# STM32F303RDT6 register map
File version: 1.0
Registers are 32-bit, access not given, reset 0x0 unless marked. A register's access mark holds for its fields unless they carry their own. Offsets are from the block's base; [hi:lo] are bit positions; {n}, {i} and the like mark numbered series.

## SYSCFG
Base 0x40010000
0x00 CFGR1
  [31:26] FPU_IE, [23:22] ENCODER_MODE, [21] I2C2FMP, [20] _I2C1_FMP, [19] I2C_PB9_FMP, [18] I2C_PB8_FMP, [17] I2C_PB7_FMP, [16] I2CPB6FMP, [15] DAC2_CH1_DMA_RMP, [14] TIM7_DAC2_DMA_RMP, [13] TIM6_DAC1_DMA_RMP, [12] TIM17_DMA_RMP, [11] TIM16_DMA_RMP, [8] ADC24_DMA_RMP, [7] DAC_TRIG_RMP, [6] TIM1_ITR3_RMP, [5] USB_IT_RMP, [25:2] s, [1:0] MEM_MODE
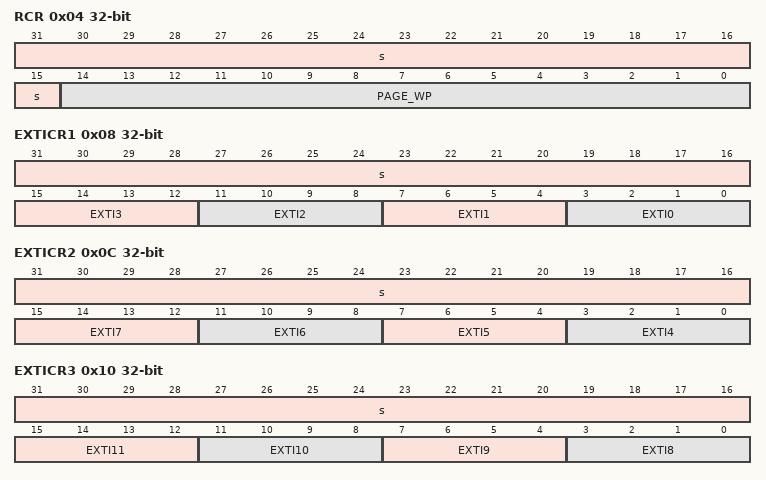
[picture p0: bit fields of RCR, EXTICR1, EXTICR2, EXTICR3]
0x04 RCR
  [31:15] s, [14:0] PAGE_WP
0x08 EXTICR1
  [31:16] s, [4n+3:4n] EXTI{n} (n=0..3)
0x0C EXTICR2
  [31:16] s, [4n-13:4n-16] EXTI{n} (n=4..7)
0x10 EXTICR3
  [31:16] s, [4n-29:4n-32] EXTI{n} (n=8..11)
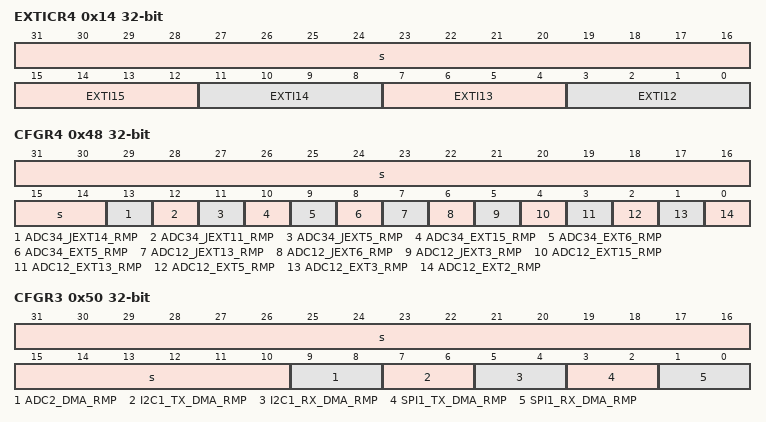
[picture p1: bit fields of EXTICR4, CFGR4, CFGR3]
0x14 EXTICR4
  [31:16] s, [4n-45:4n-48] EXTI{n} (n=12..15)
0x18 CFGR2
  [8] SRAM_PEF, [4] BYP_ADDR_PAR, [31:3] s, [2] PVD_LOCK, [1] SRAM_PARITY_LOCK, [0] LOCKUP_LOCK
0x48 CFGR4
  [31:14] s, [13] ADC34_JEXT14_RMP, [12] ADC34_JEXT11_RMP, [11] ADC34_JEXT5_RMP, [10] ADC34_EXT15_RMP, [9] ADC34_EXT6_RMP, [8] ADC34_EXT5_RMP, [7] ADC12_JEXT13_RMP, [6] ADC12_JEXT6_RMP, [5] ADC12_JEXT3_RMP, [4] ADC12_EXT15_RMP, [3] ADC12_EXT13_RMP, [2] ADC12_EXT5_RMP, [1] ADC12_EXT3_RMP, [0] ADC12_EXT2_RMP
0x50 CFGR3
  [31:10] s, [9:8] ADC2_DMA_RMP, [7:6] I2C1_TX_DMA_RMP, [5:4] I2C1_RX_DMA_RMP, [3:2] SPI1_TX_DMA_RMP, [1:0] SPI1_RX_DMA_RMP

## COMP
Base 0x40010000
0x1C COMP1_CSR
  [31] COMP1LOCK, [30] COMP1OUT, [20:18] COMPx_BLANKING, [17:16] COMP1HYST, [15] COMP1POL, [13:10] COMP1OUTSEL, [29:7] s, [6:4] COMP1INSEL, [3:2] COMP1MODE, [1] COMP1_INP_DAC, [0] COMP1EN
0x20 COMP2_CSR
  [31] COMP2LOCK, [30] COMP2OUT, [20:18] COMP2_BLANKING, [15] COMP2POL, [13:10] COMP2OUTSEL, [9] COMP2WINMODE, [29:8] s, [7] COMP2INSEL, [22:4] COMP2INMSEL, [3:2] COMP2MODE, [1] COMP2_INP_DAC, [0] COMP2EN
0x24 COMP3_CSR
  [31] COMP3LOCK, [30] COMP3OUT, [20:18] COMP3_BLANKING, [17:16] COMP3HYST, [15] COMP3POL, [13:10] COMP3OUTSEL, [7] COMP3INSEL, [6:4] COMP3INMSEL, [3:2] COMP3MODE, [29:1] s, [0] COMP3EN
0x28 COMP4_CSR
  [31] COMP4LOCK, [30] COMP4OUT, [20:18] COMP4_BLANKING, [15] COMP4POL, [13:10] COMP4OUTSEL, [9] COMP4WINMODE, [7] COMP4INSEL, [22:4] COMP4INMSEL, [3:2] COMP4MODE, [29:1] s, [0] COMP4EN
0x2C COMP5_CSR
  [31] COMP5LOCK, [30] COMP5OUT, [20:18] COMP5_BLANKING, [17:16] COMP5HYST, [15] COMP5POL, [13:10] COMP5OUTSEL, [7] COMP5INSEL, [6:4] COMP5INMSEL, [3:2] COMP5MODE, [29:1] s, [0] COMP5EN
0x30 COMP6_CSR
  [31] COMP6LOCK, [30] COMP6OUT, [20:18] COMP6_BLANKING, [15] COMP6POL, [13:10] COMP6OUTSEL, [9] COMP6WINMODE, [7] COMP6INSEL, [22:4] COMP6INMSEL, [3:2] COMP6MODE, [29:1] s, [0] COMP6EN
0x34 COMP7_CSR
  [31] COMP7LOCK, [30] COMP7OUT, [20:18] COMP7_BLANKING, [17:16] COMP7HYST, [15] COMP7POL, [13:10] COMP7OUTSEL, [7] COMP7INSEL, [6:4] COMP7INMSEL, [3:2] COMP7MODE, [29:1] s, [0] COMP7EN

## OPAMP
Base 0x40010000
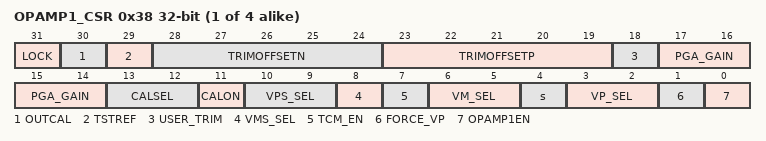
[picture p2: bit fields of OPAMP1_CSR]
{0x34+4i} OPAMP{i}_CSR (i=1..4)
  [31] LOCK, [30] OUTCAL, [29] TSTREF, [28:24] TRIMOFFSETN, [23:19] TRIMOFFSETP, [18] USER_TRIM, [17:14] PGA_GAIN, [13:12] CALSEL, [11] CALON, [10:9] VPS_SEL, [8] VMS_SEL, [7] TCM_EN, [6:5] VM_SEL, [4] s, [3:2] VP_SEL, [1] FORCE_VP, [0] OPAMP{i}EN

## EXTI
Base 0x40010400
0x00 IMR1
  [31:0] MR
0x04 EMR1
  [31:0] MR
0x08 RTSR1
  [28:23] s, [31:0] TR
0x0C FTSR1
  [28:23] s, [31:0] TR
0x10 SWIER1
  [28:23] s, [31:0] SWIER
0x14 PR1
  [28:23] s, [31:0] PR
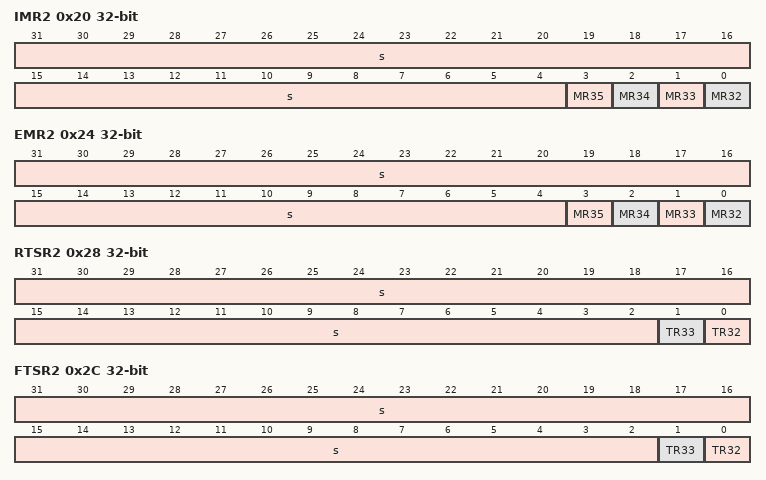
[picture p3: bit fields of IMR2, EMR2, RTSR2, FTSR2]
0x20 IMR2
  [31:4] s, [n-32] MR{n} (n=32..35)
0x24 EMR2
  [31:4] s, [n-32] MR{n} (n=32..35)
0x28 RTSR2
  [31:2] s, [1] TR33, [0] TR32
0x2C FTSR2
  [31:2] s, [1] TR33, [0] TR32
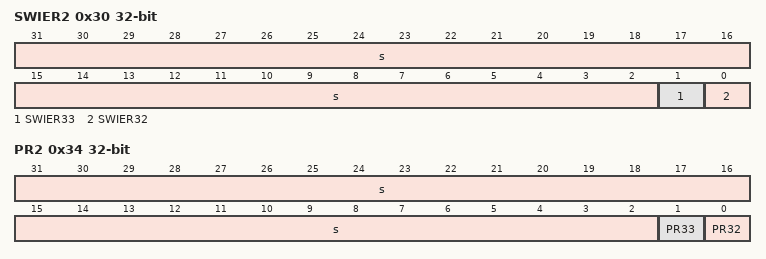
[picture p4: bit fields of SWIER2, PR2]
0x30 SWIER2
  [31:2] s, [1] SWIER33, [0] SWIER32
0x34 PR2
  [31:2] s, [1] PR33, [0] PR32

## TIM1
Base 0x40012C00
0x00 CR1
  [11] UIFREMAP, [31:10] s, [9:8] CKD, [7] ARPE, [6:5] CMS, [4] DIR, [3] OPM, [2] URS, [1] UDIS, [0] CEN
0x04 CR2
  [23:20] MMS2, [2n+6] OIS{n} (n=1..6), [13] OIS3N, [11] OIS2N, [9] OIS1N, [7] TI1S, [6:4] MMS, [3] CCDS, [2] CCUS, [31:1] s, [0] CCPC
0x08 SMCR
  [31:17] s, [15] ETP, [14] ECE, [13:12] ETPS, [11:8] ETF, [7] MSM, [6:4] TS, [3] OCCS, [16:0] SMS
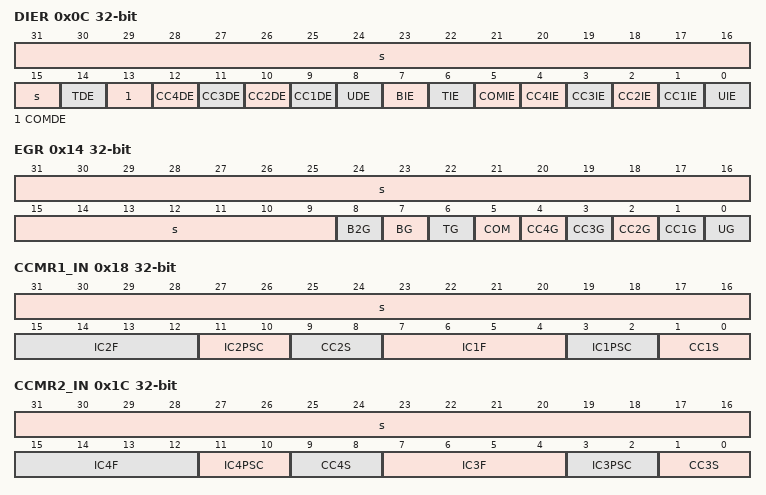
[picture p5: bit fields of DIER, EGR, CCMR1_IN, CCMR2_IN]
0x0C DIER
  [31:15] s, [14] TDE, [13] COMDE, [n+8] CC{n}DE (n=1..4), [8] UDE, [7] BIE, [6] TIE, [5] COMIE, [n] CC{n}IE (n=1..4), [0] UIE
0x10 SR
  [17] CC6IF, [16] CC5IF, [31:13] s, [n+8] CC{n}OF (n=1..4), [8] B2IF, [7] BIF, [6] TIF, [5] COMIF, [n] CC{n}IF (n=1..4), [0] UIF
0x14 EGR
  [31:9] s, [8] B2G, [7] BG, [6] TG, [5] COM, [n] CC{n}G (n=1..4), [0] UG
0x18 CCMR1_OUT
  [31:17] s, [15] OC2CE, [24:12] OC2M, [11] OC2PE, [10] OC2FE, [9:8] CC2S, [7] OC1CE, [16:4] OC1M, [3] OC1PE, [2] OC1FE, [1:0] CC1S
0x18 CCMR1_IN
  [31:16] s, [15:12] IC2F, [11:10] IC2PSC, [9:8] CC2S, [7:4] IC1F, [3:2] IC1PSC, [1:0] CC1S
0x1C CCMR2_OUT
  [31:17] s, [15] OC4CE, [24:12] OC4M, [11] OC4PE, [10] OC4FE, [9:8] CC4S, [7] OC3CE, [16:4] OC3M, [3] OC3PE, [2] OC3FE, [1:0] CC3S
0x1C CCMR2_IN
  [31:16] s, [15:12] IC4F, [11:10] IC4PSC, [9:8] CC4S, [7:4] IC3F, [3:2] IC3PSC, [1:0] CC3S
0x20 CCER
  [4n-3] CC{n}P (n=1..6), [4n-4] CC{n}E (n=1..6), [31:14] s, [11] CC3NP, [10] CC3NE, [7] CC2NP, [6] CC2NE, [3] CC1NP, [2] CC1NE
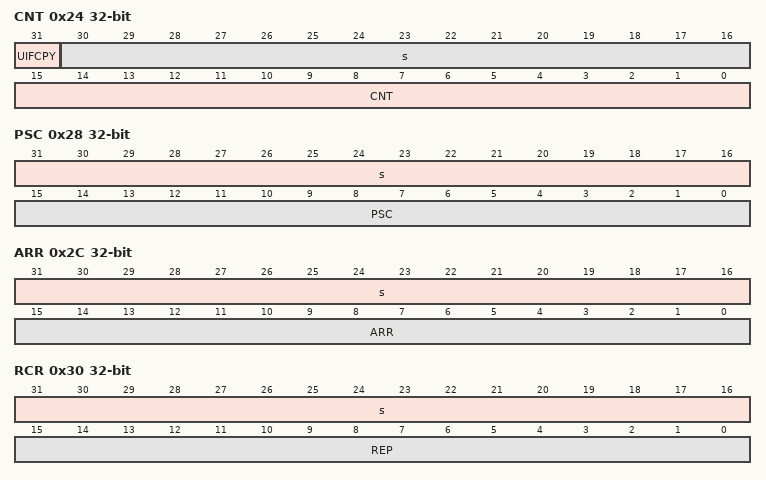
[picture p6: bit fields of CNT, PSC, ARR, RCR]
0x24 CNT
  [31] UIFCPY, [30:16] s, [15:0] CNT
0x28 PSC
  [31:16] s, [15:0] PSC
0x2C ARR
  [31:16] s, [15:0] ARR
0x30 RCR
  [31:16] s, [15:0] REP
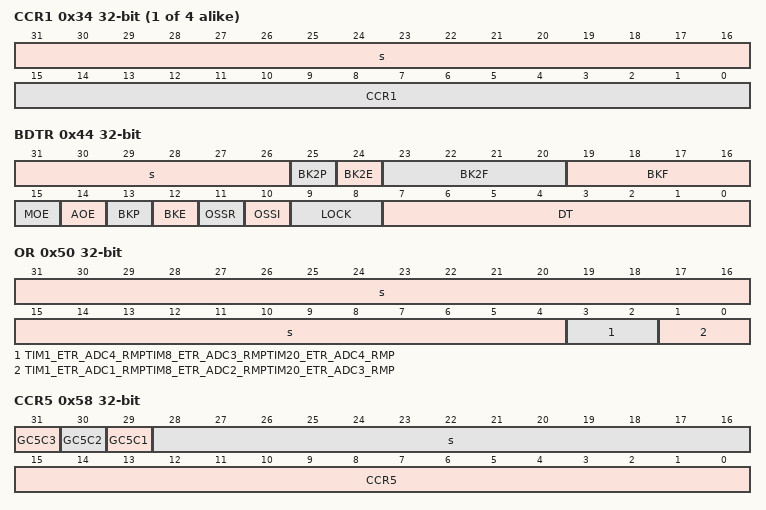
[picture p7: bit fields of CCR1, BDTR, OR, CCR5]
{0x30+4i} CCR{i} (i=1..4)
  [31:16] s, [15:0] CCR{i}
0x44 BDTR
  [31:26] s, [25] BK2P, [24] BK2E, [23:20] BK2F, [19:16] BKF, [15] MOE, [14] AOE, [13] BKP, [12] BKE, [11] OSSR, [10] OSSI, [9:8] LOCK, [7:0] DT
0x48 DCR
  [12:8] DBL, [31:5] s, [4:0] DBA
0x4C DMAR
  [31:0] DMAB
0x50 OR
  [31:4] s, [3:2] TIM1_ETR_ADC4_RMPTIM8_ETR_ADC3_RMPTIM20_ETR_ADC4_RMP, [1:0] TIM1_ETR_ADC1_RMPTIM8_ETR_ADC2_RMPTIM20_ETR_ADC3_RMP
0x54 CCMR3_OUT
  [15] OC6CE, [24:12] OC6M, [11] OC6PE, [10] OC6FE, [7] OC5CE, [16:4] OC5M, [3] OC5PE, [2] OC5FE, [31:0] s
0x58 CCR5
  [31] GC5C3, [30] GC5C2, [29] GC5C1, [28:16] s, [15:0] CCR5
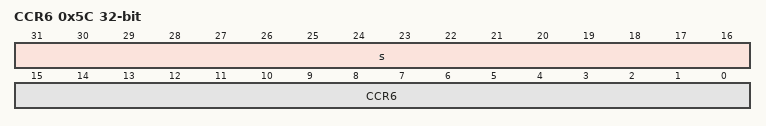
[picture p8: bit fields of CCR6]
0x5C CCR6
  [31:16] s, [15:0] CCR6

## TIM8
Base 0x40013400
Same registers: TIM20 0x40015000
Registers as TIM1; these are added or differ:
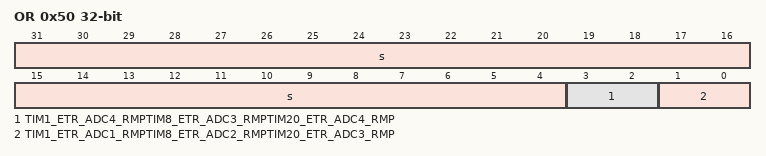
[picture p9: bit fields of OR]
0x50 OR
  [31:4] s, [3:2] TIM1_ETR_ADC4_RMPTIM8_ETR_ADC3_RMPTIM20_ETR_ADC4_RMP, [1:0] TIM1_ETR_ADC1_RMPTIM8_ETR_ADC2_RMPTIM20_ETR_ADC3_RMP
